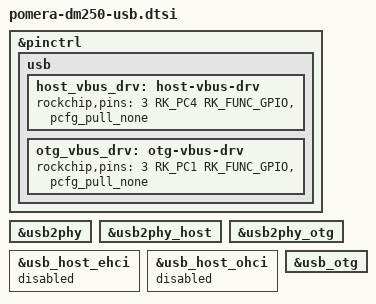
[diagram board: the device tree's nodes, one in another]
// SPDX-License-Identifier: (GPL-2.0+ OR MIT)

&pinctrl {
	usb {
		host_vbus_drv: host-vbus-drv {
			rockchip,pins = <3 RK_PC4 RK_FUNC_GPIO &pcfg_pull_none>;
		};
                
		otg_vbus_drv: otg-vbus-drv {
			rockchip,pins = <3 RK_PC1 RK_FUNC_GPIO &pcfg_pull_none>;
		};
	};
};

&usb2phy {
	status = "okay";
};

&usb2phy_host {
	status = "okay";
};

&usb2phy_otg {
	status = "okay";
};

&usb_host_ehci {
	status = "disabled";
};

&usb_host_ohci {
	status = "disabled";
};

&usb_otg {
	status = "okay";
};
